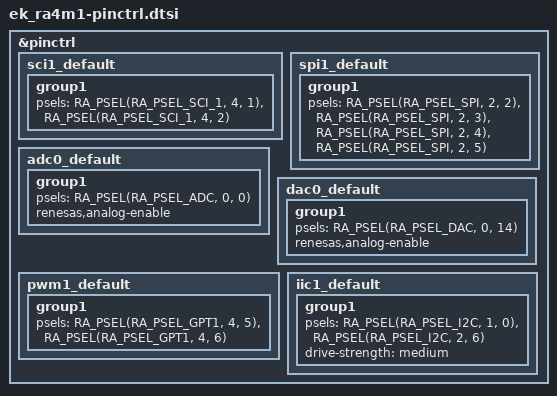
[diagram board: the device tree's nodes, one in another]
/*
 * Copyright (c) 2024-2025 Renesas Electronics Corporation
 * SPDX-License-Identifier: Apache-2.0
 */

&pinctrl {
	sci1_default: sci1_default {
		group1 {
			/* tx rx */
			psels = <RA_PSEL(RA_PSEL_SCI_1, 4, 1)>,
				<RA_PSEL(RA_PSEL_SCI_1, 4, 2)>;
		};
	};

	spi1_default: spi1_default {
		group1 {
			/* MISO MOSI RSPCK SSL */
			psels = <RA_PSEL(RA_PSEL_SPI, 2, 2)>,
				<RA_PSEL(RA_PSEL_SPI, 2, 3)>,
				<RA_PSEL(RA_PSEL_SPI, 2, 4)>,
				<RA_PSEL(RA_PSEL_SPI, 2, 5)>;
		};
	};

	adc0_default: adc0_default {
		group1 {
			/* input */
			psels = <RA_PSEL(RA_PSEL_ADC, 0, 0)>;
			renesas,analog-enable;
		};
	};

	dac0_default: dac0_default {
		group1 {
			/* output */
			psels = <RA_PSEL(RA_PSEL_DAC, 0, 14)>;
			renesas,analog-enable;
		};
	};

	pwm1_default: pwm1_default {
		group1 {
			/* GTIOC1A GTIOC1B */
			psels = <RA_PSEL(RA_PSEL_GPT1, 4, 5)>,
				<RA_PSEL(RA_PSEL_GPT1, 4, 6)>;
		};
	};

	iic1_default: iic1_default {
		group1 {
			/* SCL1 SDA1 */
			psels = <RA_PSEL(RA_PSEL_I2C, 1, 0)>,
				<RA_PSEL(RA_PSEL_I2C, 2, 6)>;
			drive-strength = "medium";
		};
	};
};
